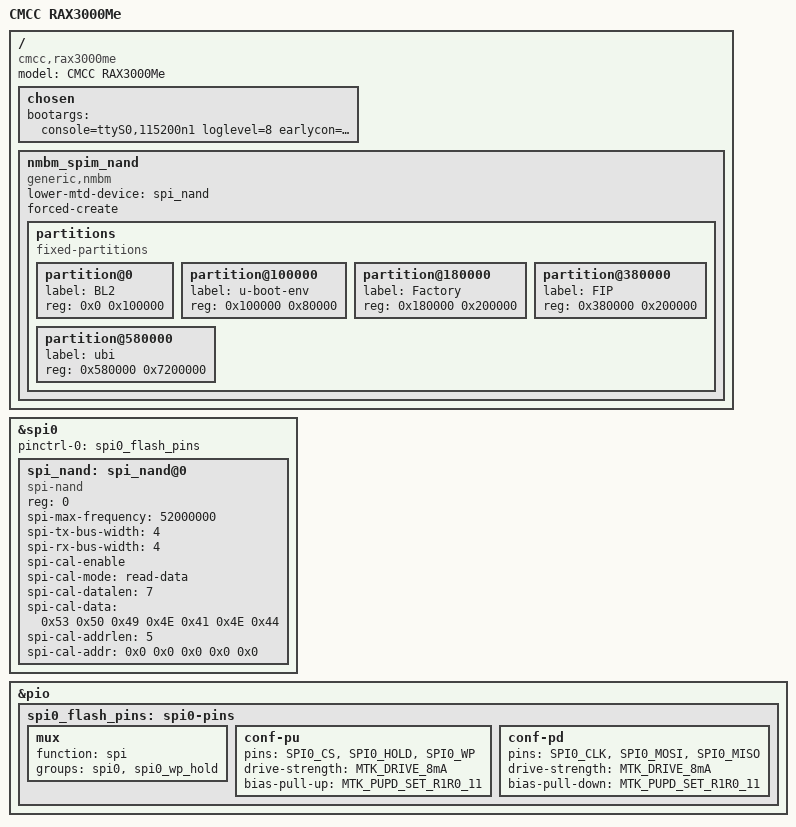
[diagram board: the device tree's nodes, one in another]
/dts-v1/;
#include "mt7981-cmcc-rax3000m.dtsi"

/ {
	model = "CMCC RAX3000Me";
	compatible = "cmcc,rax3000me", "mediatek,mt7981";

	chosen {
		bootargs = "console=ttyS0,115200n1 loglevel=8 \
			    earlycon=uart8250,mmio32,0x11002000";
	};

	nmbm_spim_nand {
		compatible = "generic,nmbm";
		#address-cells = <1>;
		#size-cells = <1>;

		lower-mtd-device = <&spi_nand>;
		forced-create;

		partitions {
			compatible = "fixed-partitions";
			#address-cells = <1>;
			#size-cells = <1>;

			partition@0 {
				label = "BL2";
				reg = <0x0 0x100000>;
			};

			partition@100000 {
				label = "u-boot-env";
				reg = <0x100000 0x80000>;
			};

			partition@180000 {
				label = "Factory";
				reg = <0x180000 0x200000>;
			};

			partition@380000 {
				label = "FIP";
				reg = <0x380000 0x200000>;
			};

			partition@580000 {
				label = "ubi";
				reg = <0x580000 0x7200000>;
			};
		};
	};
};

&spi0 {
	pinctrl-names = "default";
	pinctrl-0 = <&spi0_flash_pins>;
	status = "okay";

	spi_nand: spi_nand@0 {
		#address-cells = <1>;
		#size-cells = <1>;
		compatible = "spi-nand";
		reg = <0>;
		spi-max-frequency = <52000000>;
		spi-tx-bus-width = <4>;
		spi-rx-bus-width = <4>;
		spi-cal-enable;
		spi-cal-mode = "read-data";
		spi-cal-datalen = <7>;
		spi-cal-data = /bits/ 8 <0x53 0x50 0x49 0x4E 0x41 0x4E 0x44>; /* 'SPINAND' */
		spi-cal-addrlen = <5>;
		spi-cal-addr = /bits/ 32 <0x0 0x0 0x0 0x0 0x0>;
	};
};

&pio {
	spi0_flash_pins: spi0-pins {
		mux {
			function = "spi";
			groups = "spi0", "spi0_wp_hold";
		};

		conf-pu {
			pins = "SPI0_CS", "SPI0_HOLD", "SPI0_WP";
			drive-strength = <MTK_DRIVE_8mA>;
			bias-pull-up = <MTK_PUPD_SET_R1R0_11>;
		};

		conf-pd {
			pins = "SPI0_CLK", "SPI0_MOSI", "SPI0_MISO";
			drive-strength = <MTK_DRIVE_8mA>;
			bias-pull-down = <MTK_PUPD_SET_R1R0_11>;
		};
	};
};
